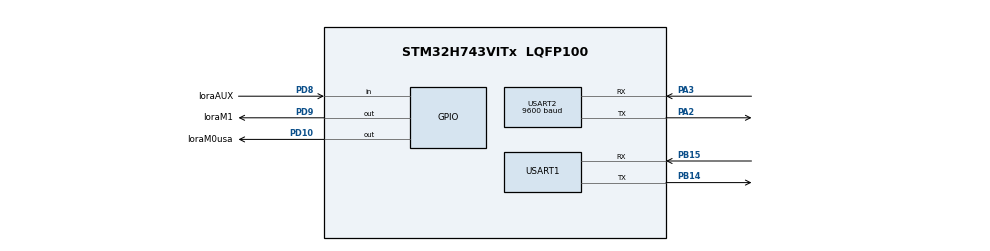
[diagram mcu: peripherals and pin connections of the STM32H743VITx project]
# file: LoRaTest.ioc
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Mcu.Family=STM32H7
Mcu.Name=STM32H743VITx
Mcu.Package=LQFP100
NVIC.PriorityGroup=NVIC_PRIORITYGROUP_4
NVIC.USART1_IRQn=true\:0\:0\:false\:false\:true\:true\:true
NVIC.USART2_IRQn=true\:0\:0\:false\:false\:true\:true\:true
PA2.Mode=Asynchronous
PA2.Signal=USART2_TX
PA3.Mode=Asynchronous
PA3.Signal=USART2_RX
PB14.Mode=Asynchronous
PB14.Signal=USART1_TX
PB15.Mode=Asynchronous
PB15.Signal=USART1_RX
PD10.GPIO_Label=loraM0usa
PD10.GPIO_PuPd=GPIO_PULLDOWN
PD10.Signal=GPIO_Output
PD8.GPIO_Label=loraAUX
PD8.GPIO_PuPd=GPIO_PULLDOWN
PD8.Signal=GPIO_Input
PD9.GPIO_Label=loraM1
PD9.GPIO_PuPd=GPIO_PULLDOWN
PD9.Signal=GPIO_Output
PH0-OSC_IN\ (PH0).Mode=HSE-External-Oscillator
PH0-OSC_IN\ (PH0).Signal=RCC_OSC_IN
PH1-OSC_OUT\ (PH1).Mode=HSE-External-Oscillator
PH1-OSC_OUT\ (PH1).Signal=RCC_OSC_OUT
ProjectManager.HeapSize=0x200
ProjectManager.StackSize=0x400
ProjectManager.TargetToolchain=STM32CubeIDE
RCC.ADCFreq_Value=129000000
RCC.APB1Freq_Value=32000000
RCC.APB2Freq_Value=32000000
RCC.APB3Freq_Value=64000000
RCC.APB4Freq_Value=64000000
RCC.CortexFreq_Value=64000000
RCC.D2PPRE1=RCC_APB1_DIV2
RCC.D2PPRE2=RCC_APB2_DIV2
RCC.HCLKFreq_Value=64000000
RCC.SYSCLKFreq_VALUE=64000000
RCC.USBFreq_Value=129000000
USART1.VirtualMode-Asynchronous=VM_ASYNC
USART2.BaudRate=9600
USART2.VirtualMode-Asynchronous=VM_ASYNC
board=custom

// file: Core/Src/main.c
/* USER CODE BEGIN Header */
/**
  ******************************************************************************
  * @file           : main.c
  * @brief          : Main program body
  ******************************************************************************
  * @attention
  *
  * Copyright (c) 2022 STMicroelectronics.
  * All rights reserved.
  *
  * This software is licensed under terms that can be found in the LICENSE file
  * in the root directory of this software component.
  * If no LICENSE file comes with this software, it is provided AS-IS.
  *
  ******************************************************************************
  */
/* USER CODE END Header */
#include "main.h"

/* USER CODE BEGIN Includes */
#include "string.h"
#include "stdio.h"
#include "stdint.h"
#include "LoRa.h"
/* USER CODE END Includes */

UART_HandleTypeDef huart1;
UART_HandleTypeDef huart2;

/* USER CODE BEGIN PV */
#define PCUart 	&huart1
#define LoraUart &huart2
/* USER CODE END PV */

void SystemClock_Config(void);
static void MX_GPIO_Init(void);
static void MX_USART1_UART_Init(void);
static void MX_USART2_UART_Init(void);

/* USER CODE BEGIN 0 */
#define RxBufSIZE   10
#define MainBufSIZE 240

uint8_t RxBuf[RxBufSIZE];
uint8_t MainBuf[MainBufSIZE];
uint8_t ii=0;

/*void HAL_UART_RxCpltCallback(UART_HandleTypeDef *huart)
{
	if(huart==LoraUart)
	{
		MainBuf[ii++] = RxBuf[0];
	}
	if(ii==178)
		ii=0;
	HAL_UART_Receive_IT(LoraUart, RxBuf, 1);
}*/

/* USER CODE END 0 */

int main(void)
{

  /* MCU Configuration--------------------------------------------------------*/

  /* Reset of all peripherals, Initializes the Flash interface and the Systick. */
  HAL_Init();

  /* Configure the system clock */
  SystemClock_Config();

  /* Initialize all configured peripherals */
  MX_GPIO_Init();
  MX_USART1_UART_Init();
  MX_USART2_UART_Init();
  /* USER CODE BEGIN 2 */
  LoRaE22_Init(&huart1, loraAUX_GPIO_Port, loraM0_GPIO_Port, loraM1_GPIO_Port,
      loraAUX_Pin, loraM0_Pin, loraM1_Pin);

  HAL_UART_Receive_IT(LoraUart, RxBuf, 1);
  uint8_t TxBuffer[200] = {'\0'};
  uint8_t txHeader[] = {0x00, 0x3f, 0x12};
  uint8_t i=0;

  /* USER CODE END 2 */

  /* Infinite loop */
  /* USER CODE BEGIN WHILE */
  while (1)
  {
	  if(HAL_GPIO_ReadPin(loraAUX_GPIO_Port, loraAUX_Pin)==GPIO_PIN_SET)
	  {
		  HAL_StatusTypeDef a = HAL_UART_Transmit(LoraUart, txHeader, sizeof(txHeader), HAL_MAX_DELAY);
		  sprintf(TxBuffer, "%d\n", i++/*, "$467710,3,03/02/202_12/30/45,101368.02,1368.12,123.65,213.45,89.80,10.36,22.87,13.75,38.512487,33.563017,125.89,38.525433,33.548497,135.89,YUKSELME,12.48,10.69,210.39,5,EVET"*/);
		  HAL_UART_Transmit(LoraUart, TxBuffer, sizeof(TxBuffer), HAL_MAX_DELAY);
	  }
	  if(i==5)
	  {
		  i=0;
	  }
    /* USER CODE END WHILE */

  }
}

void SystemClock_Config(void)
{
  RCC_OscInitTypeDef RCC_OscInitStruct = {0};
  RCC_ClkInitTypeDef RCC_ClkInitStruct = {0};

  /** Supply configuration update enable
  */
  HAL_PWREx_ConfigSupply(PWR_LDO_SUPPLY);
  /** Configure the main internal regulator output voltage
  */
  __HAL_PWR_VOLTAGESCALING_CONFIG(PWR_REGULATOR_VOLTAGE_SCALE3);

  while(!__HAL_PWR_GET_FLAG(PWR_FLAG_VOSRDY)) {}
  /** Initializes the RCC Oscillators according to the specified parameters
  * in the RCC_OscInitTypeDef structure.
  */
  RCC_OscInitStruct.OscillatorType = RCC_OSCILLATORTYPE_HSI;
  RCC_OscInitStruct.HSIState = RCC_HSI_DIV1;
  RCC_OscInitStruct.HSICalibrationValue = RCC_HSICALIBRATION_DEFAULT;
  RCC_OscInitStruct.PLL.PLLState = RCC_PLL_NONE;
  if (HAL_RCC_OscConfig(&RCC_OscInitStruct) != HAL_OK)
  {
    Error_Handler();
  }
  /** Initializes the CPU, AHB and APB buses clocks
  */
  RCC_ClkInitStruct.ClockType = RCC_CLOCKTYPE_HCLK|RCC_CLOCKTYPE_SYSCLK
                              |RCC_CLOCKTYPE_PCLK1|RCC_CLOCKTYPE_PCLK2
                              |RCC_CLOCKTYPE_D3PCLK1|RCC_CLOCKTYPE_D1PCLK1;
  RCC_ClkInitStruct.SYSCLKSource = RCC_SYSCLKSOURCE_HSI;
  RCC_ClkInitStruct.SYSCLKDivider = RCC_SYSCLK_DIV1;
  RCC_ClkInitStruct.AHBCLKDivider = RCC_HCLK_DIV1;
  RCC_ClkInitStruct.APB3CLKDivider = RCC_APB3_DIV1;
  RCC_ClkInitStruct.APB1CLKDivider = RCC_APB1_DIV2;
  RCC_ClkInitStruct.APB2CLKDivider = RCC_APB2_DIV2;
  RCC_ClkInitStruct.APB4CLKDivider = RCC_APB4_DIV1;

  if (HAL_RCC_ClockConfig(&RCC_ClkInitStruct, FLASH_LATENCY_1) != HAL_OK)
  {
    Error_Handler();
  }
}

static void MX_USART1_UART_Init(void)
{

  huart1.Instance = USART1;
  huart1.Init.BaudRate = 115200;
  huart1.Init.WordLength = UART_WORDLENGTH_8B;
  huart1.Init.StopBits = UART_STOPBITS_1;
  huart1.Init.Parity = UART_PARITY_NONE;
  huart1.Init.Mode = UART_MODE_TX_RX;
  huart1.Init.HwFlowCtl = UART_HWCONTROL_NONE;
  huart1.Init.OverSampling = UART_OVERSAMPLING_16;
  huart1.Init.OneBitSampling = UART_ONE_BIT_SAMPLE_DISABLE;
  huart1.Init.ClockPrescaler = UART_PRESCALER_DIV1;
  huart1.AdvancedInit.AdvFeatureInit = UART_ADVFEATURE_NO_INIT;
  if (HAL_UART_Init(&huart1) != HAL_OK)
  {
    Error_Handler();
  }
  if (HAL_UARTEx_SetTxFifoThreshold(&huart1, UART_TXFIFO_THRESHOLD_1_8) != HAL_OK)
  {
    Error_Handler();
  }
  if (HAL_UARTEx_SetRxFifoThreshold(&huart1, UART_RXFIFO_THRESHOLD_1_8) != HAL_OK)
  {
    Error_Handler();
  }
  if (HAL_UARTEx_DisableFifoMode(&huart1) != HAL_OK)
  {
    Error_Handler();
  }

}

static void MX_USART2_UART_Init(void)
{

  huart2.Instance = USART2;
  huart2.Init.BaudRate = 9600;
  huart2.Init.WordLength = UART_WORDLENGTH_8B;
  huart2.Init.StopBits = UART_STOPBITS_1;
  huart2.Init.Parity = UART_PARITY_NONE;
  huart2.Init.Mode = UART_MODE_TX_RX;
  huart2.Init.HwFlowCtl = UART_HWCONTROL_NONE;
  huart2.Init.OverSampling = UART_OVERSAMPLING_16;
  huart2.Init.OneBitSampling = UART_ONE_BIT_SAMPLE_DISABLE;
  huart2.Init.ClockPrescaler = UART_PRESCALER_DIV1;
  huart2.AdvancedInit.AdvFeatureInit = UART_ADVFEATURE_NO_INIT;
  if (HAL_UART_Init(&huart2) != HAL_OK)
  {
    Error_Handler();
  }
  if (HAL_UARTEx_SetTxFifoThreshold(&huart2, UART_TXFIFO_THRESHOLD_1_8) != HAL_OK)
  {
    Error_Handler();
  }
  if (HAL_UARTEx_SetRxFifoThreshold(&huart2, UART_RXFIFO_THRESHOLD_1_8) != HAL_OK)
  {
    Error_Handler();
  }
  if (HAL_UARTEx_DisableFifoMode(&huart2) != HAL_OK)
  {
    Error_Handler();
  }

}

static void MX_GPIO_Init(void)
{
  GPIO_InitTypeDef GPIO_InitStruct = {0};

  /* GPIO Ports Clock Enable */
  __HAL_RCC_GPIOH_CLK_ENABLE();
  __HAL_RCC_GPIOA_CLK_ENABLE();
  __HAL_RCC_GPIOB_CLK_ENABLE();
  __HAL_RCC_GPIOD_CLK_ENABLE();

  /*Configure GPIO pin Output Level */
  HAL_GPIO_WritePin(GPIOD, loraM1_Pin|loraM0_Pin, GPIO_PIN_RESET);

  /*Configure GPIO pin : loraAUX_Pin */
  GPIO_InitStruct.Pin = loraAUX_Pin;
  GPIO_InitStruct.Mode = GPIO_MODE_INPUT;
  GPIO_InitStruct.Pull = GPIO_PULLDOWN;
  HAL_GPIO_Init(loraAUX_GPIO_Port, &GPIO_InitStruct);

  /*Configure GPIO pins : loraM1_Pin loraM0usa_Pin */
  GPIO_InitStruct.Pin = loraM1_Pin|loraM0_Pin;
  GPIO_InitStruct.Mode = GPIO_MODE_OUTPUT_PP;
  GPIO_InitStruct.Pull = GPIO_PULLDOWN;
  GPIO_InitStruct.Speed = GPIO_SPEED_FREQ_LOW;
  HAL_GPIO_Init(GPIOD, &GPIO_InitStruct);

}

void Error_Handler(void)
{
  __disable_irq();
  while (1)
  {
  }
}
